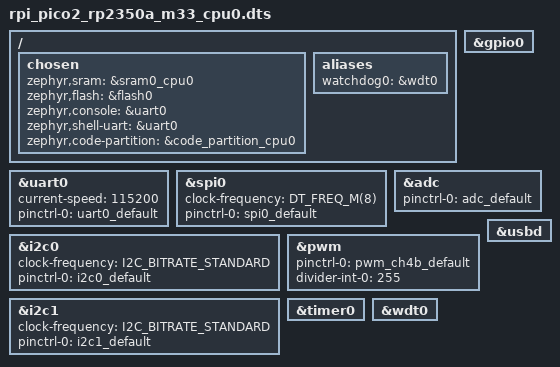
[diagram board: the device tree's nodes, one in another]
/*
 * Copyright (c) 2024 Andrew Featherstone
 *
 * SPDX-License-Identifier: Apache-2.0
 */

/dts-v1/;

/* The build system assumes that there's a cpucluster-specific file.
 *
 * This file provides composition of the device tree:
 * 1. The common features of the SoC
 * 2. Core-specific configuration.
 * 3. Board-specific configuration.
 */
#include <raspberrypi/rpi_pico/rp2350a.dtsi>
#include <raspberrypi/rpi_pico/m33.dtsi>

#include "rpi_pico2.dtsi"
#include "../common/rpi_pico-led.dtsi"

/ {
	chosen {
		zephyr,sram = &sram0_cpu0;
		zephyr,flash = &flash0;
		zephyr,console = &uart0;
		zephyr,shell-uart = &uart0;
		zephyr,code-partition = &code_partition_cpu0;
	};

	aliases {
		watchdog0 = &wdt0;
	};
};

&uart0 {
	current-speed = <115200>;
	status = "okay";
	pinctrl-0 = <&uart0_default>;
	pinctrl-names = "default";
};

gpio0_lo: &gpio0 {
	status = "okay";
};

&spi0 {
	clock-frequency = <DT_FREQ_M(8)>;
	pinctrl-0 = <&spi0_default>;
	pinctrl-names = "default";
};

&i2c0 {
	clock-frequency = <I2C_BITRATE_STANDARD>;
	pinctrl-0 = <&i2c0_default>;
	pinctrl-names = "default";
	status = "okay";
};

&i2c1 {
	clock-frequency = <I2C_BITRATE_STANDARD>;
	pinctrl-0 = <&i2c1_default>;
	pinctrl-names = "default";
	status = "okay";
};

&adc {
	pinctrl-0 = <&adc_default>;
	pinctrl-names = "default";
	status = "okay";
};

&pwm {
	pinctrl-0 = <&pwm_ch4b_default>;
	pinctrl-names = "default";
	divider-int-0 = <255>;
};

&timer0 {
	status = "okay";
};

&wdt0 {
	status = "okay";
};

zephyr_udc0: &usbd {
	status = "okay";
};

pico_serial: &uart0 {};
